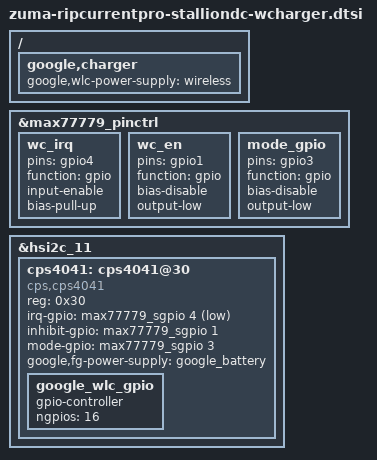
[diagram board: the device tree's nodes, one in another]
// SPDX-License-Identifier: GPL-2.0-only
/*
 * Wireless Charger device tree entries.
 *
 * Copyright 2024 Google LLC
 */

#include <arm64/exynos/exynos-pinctrl.h>
#include <dt-bindings/interrupt-controller/irq.h>

/ {
	fragment@wlc {
		target-path = "/";
		__overlay__ {
			google,charger {
				google,wlc-power-supply = "wireless";
			};
		};
	};
};

&max77779_pinctrl {
	/* QI_INT_ODL Wireless Charger Interrupt */
	wc_irq: wc_irq {
		pins = "gpio4";
		function = "gpio";
		input-enable;
		bias-pull-up;
	};

	/* QI_RX_COMM_EN_L Wireless Charger Enable */
	wc_en: wc_en {
		pins = "gpio1";
		function = "gpio";
		bias-disable;
		output-low;
	};

	/* QI_BPP_FORCE */
	mode_gpio: mode_gpio {
		pins = "gpio3";
		function = "gpio";
		bias-disable;
		output-low;
	};
};

&hsi2c_11 {
	#address-cells = <1>;
	#size-cells = <0>;

	cps4041: cps4041@30 {
		compatible = "cps,cps4041";
		reg = <0x30>;
		status = "ok";

		pinctrl-names = "default";
		irq-gpio = <&max77779_sgpio 4 GPIO_ACTIVE_LOW>;
		inhibit-gpio = <&max77779_sgpio 1 GPIO_ACTIVE_HIGH>;
		mode-gpio = <&max77779_sgpio 3 GPIO_ACTIVE_HIGH>;

		google,fg-power-supply = <&google_battery>;

		google_wlc_gpio: google_wlc_gpio {
			gpio-controller;
			#gpio-cells = <2>;
			ngpios = <16>;
		};
	};
};
